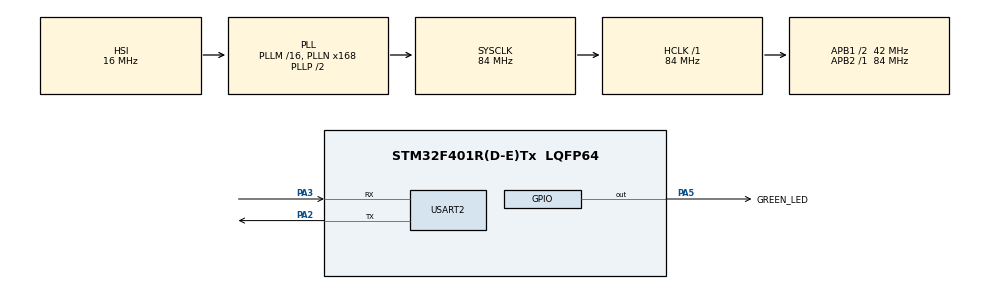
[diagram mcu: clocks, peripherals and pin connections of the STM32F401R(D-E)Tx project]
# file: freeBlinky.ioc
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Mcu.Family=STM32F4
PC15-OSC32_OUT.Mode=LSE-External-Oscillator
RCC.CortexFreq_Value=84000000
FREERTOS.Tasks01=blink01,24,128,StartBlink01,Default,NULL,Dynamic,NULL,NULL;blink02,24,128,StartBlink02,Default,NULL,Dynamic,NULL,NULL
VP_SYS_VS_tim5.Mode=TIM5
RCC.APB1CLKDivider=RCC_HCLK_DIV2
PC14-OSC32_IN.Signal=RCC_OSC32_IN
RCC.SYSCLKSource=RCC_SYSCLKSOURCE_PLLCLK
ProjectManager.StackSize=0x400
VP_FREERTOS_VS_CMSIS_V2.Mode=CMSIS_V2
PA13.Signal=SYS_JTMS-SWDIO
PA3.Mode=Asynchronous
ProjectManager.TargetToolchain=STM32CubeIDE
NVIC.TIM5_IRQn=true\:0\:0\:false\:false\:true\:false\:false\:true
RCC.HCLKFreq_Value=84000000
RCC.APB2TimFreq_Value=84000000
PC15-OSC32_OUT.Signal=RCC_OSC32_OUT
RCC.AHBFreq_Value=84000000
PA5.Signal=GPIO_Output
RCC.HSE_VALUE=25000000
board=custom
RCC.VCOOutputFreq_Value=168000000
RCC.APB2Freq_Value=84000000
PC14-OSC32_IN.Mode=LSE-External-Oscillator
PA14.Mode=Serial_Wire
PA13.Mode=Serial_Wire
Mcu.Name=STM32F401R(D-E)Tx
PA2.Signal=USART2_TX
RCC.48MHZClocksFreq_Value=42000000
RCC.SYSCLKFreq_VALUE=84000000
Mcu.Package=LQFP64
NVIC.TimeBase=TIM5_IRQn
PA5.GPIO_Label=GREEN_LED
USART2.VirtualMode=VM_ASYNC
NVIC.TimeBaseIP=TIM5
PA14.Signal=SYS_JTCK-SWCLK
ProjectManager.HeapSize=0x200
NVIC.PriorityGroup=NVIC_PRIORITYGROUP_4
RCC.PLLN=168
RCC.APB1TimFreq_Value=84000000
PA2.Mode=Asynchronous
RCC.APB1Freq_Value=42000000
PA3.Signal=USART2_RX

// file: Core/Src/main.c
/* USER CODE BEGIN Header */
/**
  ******************************************************************************
  * @file           : main.c
  * @brief          : Main program body
  ******************************************************************************
  * @attention
  *
  * <h2><center>&copy; Copyright (c) 2021 STMicroelectronics.
  * All rights reserved.</center></h2>
  *
  * This software component is licensed by ST under BSD 3-Clause license,
  * the "License"; You may not use this file except in compliance with the
  * License. You may obtain a copy of the License at:
  *                        opensource.org/licenses/BSD-3-Clause
  *
  ******************************************************************************
  */
/* USER CODE END Header */
#include "main.h"
#include "cmsis_os.h"
#include "stdio.h"

UART_HandleTypeDef huart2;

/* Definitions for blink01 */
osThreadId_t blink01Handle;
const osThreadAttr_t blink01_attributes = {
  .name = "blink01",
  .stack_size = 128 * 4,
  .priority = (osPriority_t) osPriorityNormal,
};
/* Definitions for blink02 */
osThreadId_t blink02Handle;
const osThreadAttr_t blink02_attributes = {
  .name = "blink02",
  .stack_size = 128 * 4,
  .priority = (osPriority_t) (osPriorityNormal-1),
};

void SystemClock_Config(void);
static void MX_GPIO_Init(void);
static void MX_USART2_UART_Init(void);
void StartBlink01(void *argument);
void StartBlink02(void *argument);

/* USER CODE BEGIN 0 */
int _write(int file, char *ptr, int len)
{
HAL_UART_Transmit(&huart2,(uint8_t *)ptr,len,10);
return len;
}
/* USER CODE END 0 */

int main(void)
{

  /* MCU Configuration--------------------------------------------------------*/

  /* Reset of all peripherals, Initializes the Flash interface and the Systick. */
  HAL_Init();

  /* Configure the system clock */
  SystemClock_Config();

  /* Initialize all configured peripherals */
  MX_GPIO_Init();
  MX_USART2_UART_Init();

  /* Init scheduler */
  osKernelInitialize();

  /* Create the thread(s) */
  /* creation of blink01 */
  blink01Handle = osThreadNew(StartBlink01, NULL, &blink01_attributes);

  /* creation of blink02 */
  blink02Handle = osThreadNew(StartBlink02, NULL, &blink02_attributes);

  /* Start scheduler */
  osKernelStart();

  /* We should never get here as control is now taken by the scheduler */
  /* Infinite loop */
  while (1)
  {

  }
}

void SystemClock_Config(void)
{
  RCC_OscInitTypeDef RCC_OscInitStruct = {0};
  RCC_ClkInitTypeDef RCC_ClkInitStruct = {0};

  /** Configure the main internal regulator output voltage
  */
  __HAL_RCC_PWR_CLK_ENABLE();
  __HAL_PWR_VOLTAGESCALING_CONFIG(PWR_REGULATOR_VOLTAGE_SCALE2);
  /** Initializes the RCC Oscillators according to the specified parameters
  * in the RCC_OscInitTypeDef structure.
  */
  RCC_OscInitStruct.OscillatorType = RCC_OSCILLATORTYPE_HSI;
  RCC_OscInitStruct.HSIState = RCC_HSI_ON;
  RCC_OscInitStruct.HSICalibrationValue = RCC_HSICALIBRATION_DEFAULT;
  RCC_OscInitStruct.PLL.PLLState = RCC_PLL_ON;
  RCC_OscInitStruct.PLL.PLLSource = RCC_PLLSOURCE_HSI;
  RCC_OscInitStruct.PLL.PLLM = 16;
  RCC_OscInitStruct.PLL.PLLN = 168;
  RCC_OscInitStruct.PLL.PLLP = RCC_PLLP_DIV2;
  RCC_OscInitStruct.PLL.PLLQ = 4;
  if (HAL_RCC_OscConfig(&RCC_OscInitStruct) != HAL_OK)
  {
    Error_Handler();
  }
  /** Initializes the CPU, AHB and APB buses clocks
  */
  RCC_ClkInitStruct.ClockType = RCC_CLOCKTYPE_HCLK|RCC_CLOCKTYPE_SYSCLK
                              |RCC_CLOCKTYPE_PCLK1|RCC_CLOCKTYPE_PCLK2;
  RCC_ClkInitStruct.SYSCLKSource = RCC_SYSCLKSOURCE_PLLCLK;
  RCC_ClkInitStruct.AHBCLKDivider = RCC_SYSCLK_DIV1;
  RCC_ClkInitStruct.APB1CLKDivider = RCC_HCLK_DIV2;
  RCC_ClkInitStruct.APB2CLKDivider = RCC_HCLK_DIV1;

  if (HAL_RCC_ClockConfig(&RCC_ClkInitStruct, FLASH_LATENCY_2) != HAL_OK)
  {
    Error_Handler();
  }
}

static void MX_USART2_UART_Init(void)
{

  huart2.Instance = USART2;
  huart2.Init.BaudRate = 115200;
  huart2.Init.WordLength = UART_WORDLENGTH_8B;
  huart2.Init.StopBits = UART_STOPBITS_1;
  huart2.Init.Parity = UART_PARITY_NONE;
  huart2.Init.Mode = UART_MODE_TX_RX;
  huart2.Init.HwFlowCtl = UART_HWCONTROL_NONE;
  huart2.Init.OverSampling = UART_OVERSAMPLING_16;
  if (HAL_UART_Init(&huart2) != HAL_OK)
  {
    Error_Handler();
  }

}

static void MX_GPIO_Init(void)
{
  GPIO_InitTypeDef GPIO_InitStruct = {0};

  /* GPIO Ports Clock Enable */
  __HAL_RCC_GPIOC_CLK_ENABLE();
  __HAL_RCC_GPIOA_CLK_ENABLE();

  /*Configure GPIO pin Output Level */
  HAL_GPIO_WritePin(GREEN_LED_GPIO_Port, GREEN_LED_Pin, GPIO_PIN_RESET);

  /*Configure GPIO pin : GREEN_LED_Pin */
  GPIO_InitStruct.Pin = GREEN_LED_Pin;
  GPIO_InitStruct.Mode = GPIO_MODE_OUTPUT_PP;
  GPIO_InitStruct.Pull = GPIO_NOPULL;
  GPIO_InitStruct.Speed = GPIO_SPEED_FREQ_LOW;
  HAL_GPIO_Init(GREEN_LED_GPIO_Port, &GPIO_InitStruct);

}

void StartBlink01(void *argument)
{
  /* USER CODE BEGIN 5 */
  /* Infinite loop */
  for(;;)
  {
	  HAL_GPIO_TogglePin(GREEN_LED_GPIO_Port, GREEN_LED_Pin);
	  osDelay(997);
  }
  /* USER CODE END 5 */
}

void StartBlink02(void *argument)
{
  /* USER CODE BEGIN StartBlink02 */
  /* Infinite loop */
  for(;;)
  {
	  HAL_GPIO_TogglePin(GREEN_LED_GPIO_Port, GREEN_LED_Pin);
	  osDelay(300);
  }
  /* USER CODE END StartBlink02 */
}

 /**
  * @brief  Period elapsed callback in non blocking mode
  * @note   This function is called  when TIM5 interrupt took place, inside
  * HAL_TIM_IRQHandler(). It makes a direct call to HAL_IncTick() to increment
  * a global variable "uwTick" used as application time base.
  * @param  htim : TIM handle
  * @retval None
  */
void HAL_TIM_PeriodElapsedCallback(TIM_HandleTypeDef *htim)
{
  if (htim->Instance == TIM5) {
    HAL_IncTick();
  }
}

void Error_Handler(void)
{
  __disable_irq();
  while (1)
  {
  }
}

/************************ (C) COPYRIGHT STMicroelectronics *****END OF FILE****/
